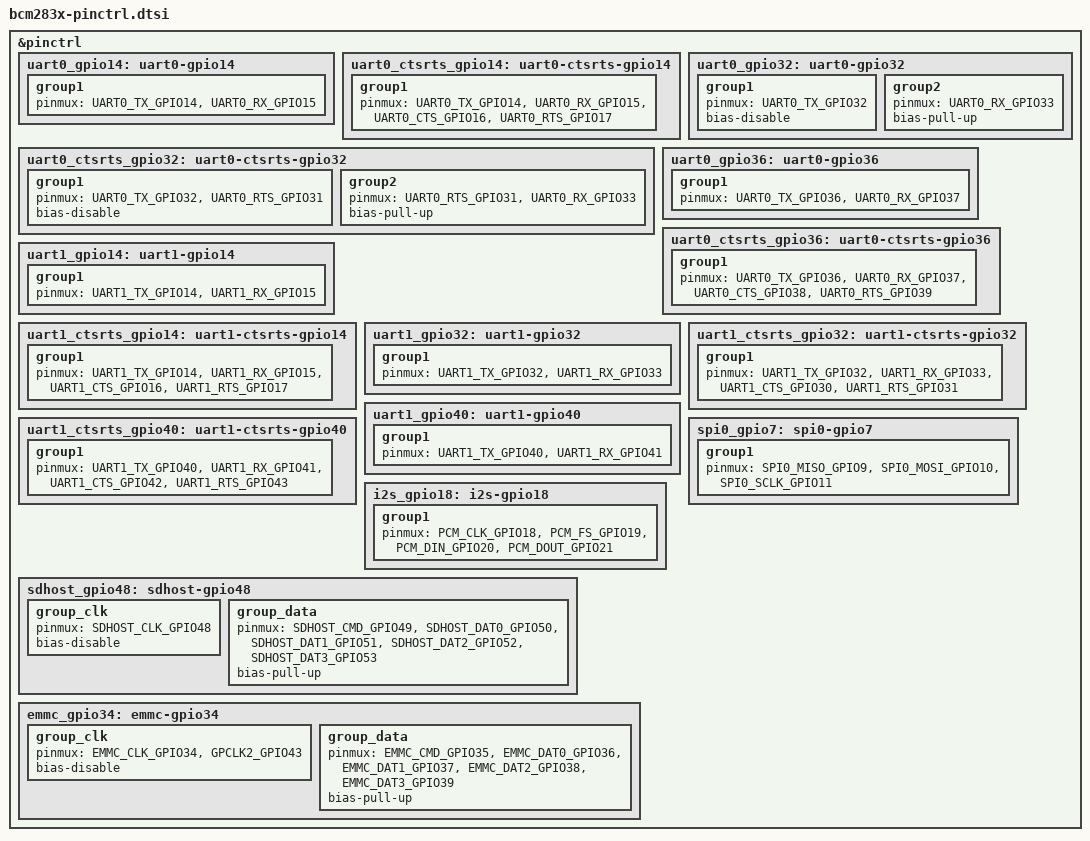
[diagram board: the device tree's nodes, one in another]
/*
 * Copyright (c) 2026 Muhammad Waleed Badar
 *
 * SPDX-License-Identifier: Apache-2.0
 */

#include <zephyr/dt-bindings/pinctrl/bcm2711-pinctrl.h>

&pinctrl {
	uart0_gpio14: uart0-gpio14 {
		group1 {
			pinmux = <UART0_TX_GPIO14>,
				 <UART0_RX_GPIO15>;
		};
	};

	uart0_ctsrts_gpio14: uart0-ctsrts-gpio14 {
		group1 {
			pinmux = <UART0_TX_GPIO14>,
				 <UART0_RX_GPIO15>,
				 <UART0_CTS_GPIO16>,
				 <UART0_RTS_GPIO17>;
		};
	};

	uart0_gpio32: uart0-gpio32 {
		group1 {
			pinmux = <UART0_TX_GPIO32>;
			bias-disable;
		};

		group2 {
			pinmux = <UART0_RX_GPIO33>;
			bias-pull-up;
		};
	};

	uart0_ctsrts_gpio32: uart0-ctsrts-gpio32 {
		group1 {
			pinmux = <UART0_TX_GPIO32>,
				 <UART0_RTS_GPIO31>;
			bias-disable;
		};

		group2 {
			pinmux = <UART0_RTS_GPIO31>,
				 <UART0_RX_GPIO33>;
			bias-pull-up;
		};
	};

	uart0_gpio36: uart0-gpio36 {
		group1 {
			pinmux = <UART0_TX_GPIO36>,
				 <UART0_RX_GPIO37>;
		};
	};

	uart0_ctsrts_gpio36: uart0-ctsrts-gpio36 {
		group1 {
			pinmux = <UART0_TX_GPIO36>,
				 <UART0_RX_GPIO37>,
				 <UART0_CTS_GPIO38>,
				 <UART0_RTS_GPIO39>;
		};
	};

	uart1_gpio14: uart1-gpio14 {
		group1 {
			pinmux = <UART1_TX_GPIO14>,
				 <UART1_RX_GPIO15>;
		};
	};

	uart1_ctsrts_gpio14: uart1-ctsrts-gpio14 {
		group1 {
			pinmux = <UART1_TX_GPIO14>,
				 <UART1_RX_GPIO15>,
				 <UART1_CTS_GPIO16>,
				 <UART1_RTS_GPIO17>;
		};
	};

	uart1_gpio32: uart1-gpio32 {
		group1 {
			pinmux = <UART1_TX_GPIO32>,
				 <UART1_RX_GPIO33>;
		};
	};

	uart1_ctsrts_gpio32: uart1-ctsrts-gpio32 {
		group1 {
			pinmux = <UART1_TX_GPIO32>,
				 <UART1_RX_GPIO33>,
				 <UART1_CTS_GPIO30>,
				 <UART1_RTS_GPIO31>;
		};
	};

	uart1_gpio40: uart1-gpio40 {
		group1 {
			pinmux = <UART1_TX_GPIO40>,
				 <UART1_RX_GPIO41>;
		};
	};

	uart1_ctsrts_gpio40: uart1-ctsrts-gpio40 {
		group1 {
			pinmux = <UART1_TX_GPIO40>,
				 <UART1_RX_GPIO41>,
				 <UART1_CTS_GPIO42>,
				 <UART1_RTS_GPIO43>;
		};
	};

	/* SPI0 full bus on GPIO 9/10/11 (ALT0). Chip select is left to
	 * cs-gpios on the controller node, so GPIO 7/8 are not muxed
	 * here. Write-only peripherals that need GPIO 9 for a D/C line
	 * should define a MOSI+SCLK-only group in the board overlay.
	 */
	spi0_gpio7: spi0-gpio7 {
		group1 {
			pinmux = <SPI0_MISO_GPIO9>,
				 <SPI0_MOSI_GPIO10>,
				 <SPI0_SCLK_GPIO11>;
		};
	};

	i2s_gpio18: i2s-gpio18 {
		group1 {
			pinmux = <PCM_CLK_GPIO18>,
				 <PCM_FS_GPIO19>,
				 <PCM_DIN_GPIO20>,
				 <PCM_DOUT_GPIO21>;
		};
	};

	/* Legacy SDHost on GPIO 48..53 ALT0: SDCLK, SDCMD, SDDAT0..3
	 * for the external microSD slot. CLK is actively driven (no
	 * pull); CMD and DAT0..3 idle pulled-up between transactions.
	 * Mirrors the BCM2711 pinctrl group; macros come from
	 * bcm2711-pinctrl.h, already #included above.
	 */
	sdhost_gpio48: sdhost-gpio48 {
		group_clk {
			pinmux = <SDHOST_CLK_GPIO48>;
			bias-disable;
		};
		group_data {
			pinmux = <SDHOST_CMD_GPIO49>,
				 <SDHOST_DAT0_GPIO50>,
				 <SDHOST_DAT1_GPIO51>,
				 <SDHOST_DAT2_GPIO52>,
				 <SDHOST_DAT3_GPIO53>;
			bias-pull-up;
		};
	};

	/* Arasan SDHCI on GPIO 34..39 (ALT3) plus GPCLK2 on GPIO 43
	 * (ALT0): SD1_CLK / SD1_CMD / SD1_DAT0..3 + the wireless-module
	 * reference clock. CLK and GPCLK2 take no pull; CMD and DAT0..3
	 * pull-up so they idle high between transactions. Mirrors the
	 * BCM2711 pinctrl group; macros come from bcm2711-pinctrl.h.
	 */
	emmc_gpio34: emmc-gpio34 {
		group_clk {
			pinmux = <EMMC_CLK_GPIO34>,
				 <GPCLK2_GPIO43>;
			bias-disable;
		};
		group_data {
			pinmux = <EMMC_CMD_GPIO35>,
				 <EMMC_DAT0_GPIO36>,
				 <EMMC_DAT1_GPIO37>,
				 <EMMC_DAT2_GPIO38>,
				 <EMMC_DAT3_GPIO39>;
			bias-pull-up;
		};
	};
};
